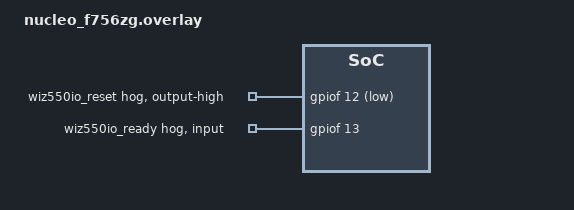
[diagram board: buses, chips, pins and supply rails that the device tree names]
/*
 * WARNING: The pin PA7 will conflict on selection of SPI_1 and ETH_STM32_HAL.
 */

/ {
	aliases {
		wiz550io-reset = &wiz550io_reset;
		wiz550io-ready = &wiz550io_ready;
	};
};

&gpiof {
	status = "okay";

	wiz550io_reset: wiz550io-reset {
		gpio-hog;
		gpios = <12 GPIO_ACTIVE_LOW>; /* D8 */
		output-high;
	};

	wiz550io_ready: wiz550io-ready {
		gpio-hog;
		gpios = <13 GPIO_ACTIVE_HIGH>; /* D7 */
		input;
	};
};
